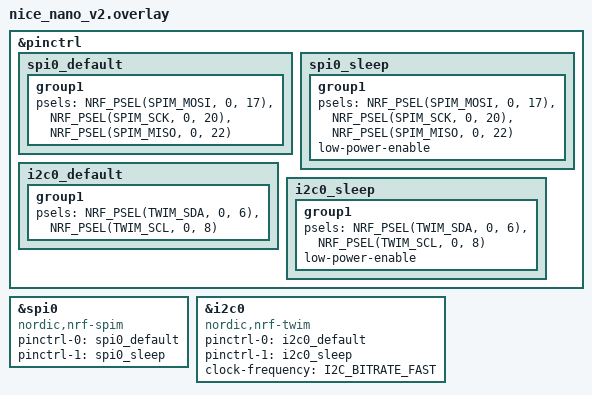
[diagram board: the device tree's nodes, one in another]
&pinctrl {
/* SPI0 pin configuration: MOSI, SCK, MISO */
    spi0_default: spi0_default {
        group1 {
                psels = <NRF_PSEL(SPIM_MOSI, 0, 17)>,
                        <NRF_PSEL(SPIM_SCK, 0, 20)>,
                        <NRF_PSEL(SPIM_MISO, 0, 22)>;
        };
    };

    spi0_sleep: spi0_sleep {
        group1 {
                psels = <NRF_PSEL(SPIM_MOSI, 0, 17)>,
                        <NRF_PSEL(SPIM_SCK, 0, 20)>,
                        <NRF_PSEL(SPIM_MISO, 0, 22)>;
            low-power-enable;
        };
    };

/* I2C0 pin configuration: SDA,SCL */
    i2c0_default: i2c0_default {
        group1 {
                psels = <NRF_PSEL(TWIM_SDA, 0, 6)>,
                        <NRF_PSEL(TWIM_SCL, 0, 8)>;
            };
    };

    i2c0_sleep: i2c0_sleep {
        group1 {
                psels = <NRF_PSEL(TWIM_SDA, 0, 6)>,
                        <NRF_PSEL(TWIM_SCL, 0, 8)>;
            low-power-enable;
        };
    };
};

&spi0 {
        compatible = "nordic,nrf-spim";
        pinctrl-0 = <&spi0_default>;
        pinctrl-1 = <&spi0_sleep>;
        pinctrl-names = "default", "sleep";
};

&i2c0 {
        compatible = "nordic,nrf-twim";
        status = "okay";
        pinctrl-0 = <&i2c0_default>;
        pinctrl-1 = <&i2c0_sleep>;
        pinctrl-names = "default", "sleep";
        clock-frequency = <I2C_BITRATE_FAST>;
};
